# MB9BF32xS register map
File version: 1.0
CPU: 
Registers are 8-bit, read-write, reset 0x0 unless marked. A register's access mark holds for its fields unless they carry their own. Offsets are from the block's base; [hi:lo] are bit positions; {n}, {i} and the like mark numbered series.

## RTC — peripheral RTC
Base 0x4003B000
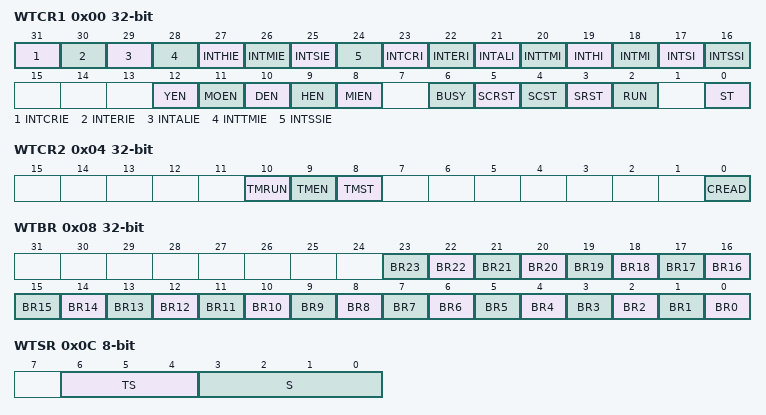
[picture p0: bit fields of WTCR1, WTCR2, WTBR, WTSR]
0x00 WTCR1 32-bit
  [31] INTCRIE, [30] INTERIE, [29] INTALIE, [28] INTTMIE, [27] INTHIE, [26] INTMIE, [25] INTSIE, [24] INTSSIE, [23] INTCRI, [22] INTERI, [21] INTALI, [20] INTTMI, [19] INTHI, [18] INTMI, [17] INTSI, [16] INTSSI, [12] YEN, [11] MOEN, [10] DEN, [9] HEN, [8] MIEN, [6] BUSY ro, [5] SCRST, [4] SCST, [3] SRST, [2] RUN ro, [0] ST
0x04 WTCR2 32-bit
  [10] TMRUN ro, [9] TMEN, [8] TMST, [0] CREAD
0x08 WTBR 32-bit
  [n] BR{n} (n=0..23)
0x0C WTSR
  [6:4] TS, [3:0] S
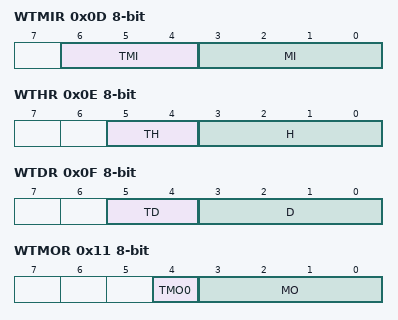
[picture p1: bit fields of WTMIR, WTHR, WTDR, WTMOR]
0x0D WTMIR
  [6:4] TMI, [3:0] MI
0x0E WTHR
  [5:4] TH, [3:0] H
0x0F WTDR
  [5:4] TD, [3:0] D
0x10 WTDW
  [2:0] DW
0x11 WTMOR
  [4] TMO0, [3:0] MO
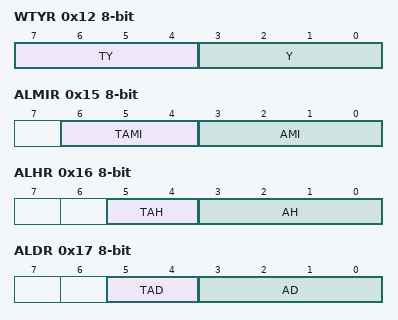
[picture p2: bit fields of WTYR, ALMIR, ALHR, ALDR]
0x12 WTYR
  [7:4] TY, [3:0] Y
0x15 ALMIR
  [6:4] TAMI, [3:0] AMI
0x16 ALHR
  [5:4] TAH, [3:0] AH
0x17 ALDR
  [5:4] TAD, [3:0] AD
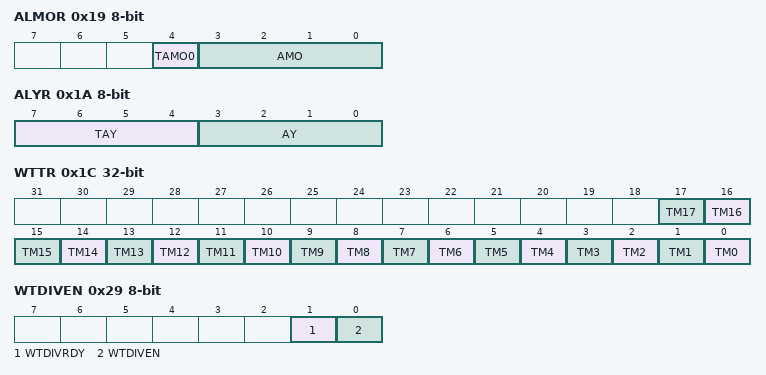
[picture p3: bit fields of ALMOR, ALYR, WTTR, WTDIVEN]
0x19 ALMOR
  [4] TAMO0, [3:0] AMO
0x1A ALYR
  [7:4] TAY, [3:0] AY
0x1C WTTR 32-bit
  [n] TM{n} (n=0..17)
0x20 WTCLKS
  [0] WTCLKS
0x21 WTCLKM ro
  [1:0] WTCLKM
0x24 WTCAL 16-bit
  [9:0] WTCAL
0x26 WTCALEN
  [0] WTCALEN
0x28 WTDIV
  [3:0] WTDIV
0x29 WTDIVEN
  [1] WTDIVRDY ro, [0] WTDIVEN
0x2C WTCALPRD reset 0x13
  [5:0] WTCALPRD
0x30 WTCOSEL
  [0] WTCOSEL

## CRC — peripheral CRC
Base 0x40039000
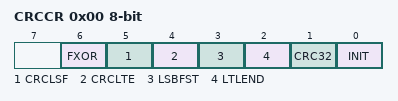
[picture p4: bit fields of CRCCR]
0x00 CRCCR
  [6] FXOR, [5] CRCLSF, [4] CRCLTE, [3] LSBFST, [2] LTLEND, [1] CRC32, [0] INIT
0x04 CRCINIT 32-bit reset 0xFFFFFFFF
  [31:0] D
0x08 CRCIN 32-bit
  [31:0] D
0x0C CRCR 32-bit ro reset 0xFFFFFFFF
  [31:0] D

## EXBUS — peripheral EXBUS
Base 0x4003F000
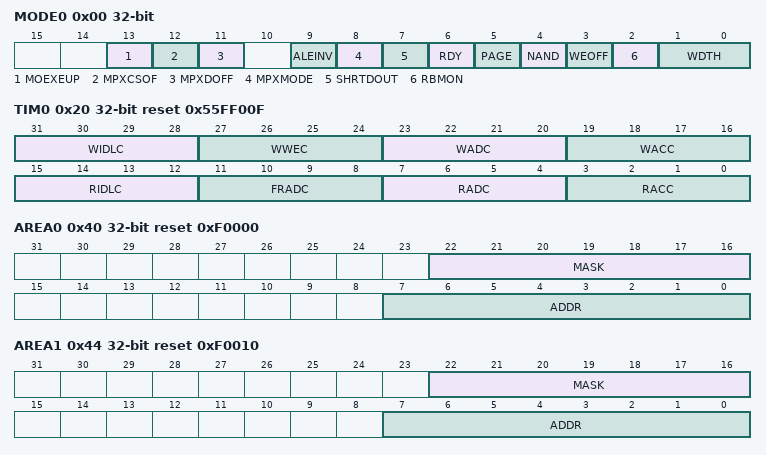
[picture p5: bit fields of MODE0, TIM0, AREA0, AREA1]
0x00 MODE0 32-bit
  [13] MOEXEUP, [12] MPXCSOF, [11] MPXDOFF, [9] ALEINV, [8] MPXMODE, [7] SHRTDOUT, [6] RDY, [5] PAGE, [4] NAND, [3] WEOFF, [2] RBMON, [1:0] WDTH
{0x0+4i} MODE{i} 32-bit reset not defined (i=1..7)
0x20 TIM0 32-bit reset 0x55FF00F
  [31:28] WIDLC, [27:24] WWEC, [23:20] WADC, [19:16] WACC, [15:12] RIDLC, [11:8] FRADC, [7:4] RADC, [3:0] RACC
{0x20+4i} TIM{i} 32-bit reset not defined (i=1..7)
0x40 AREA0 32-bit reset 0xF0000
  [22:16] MASK, [7:0] ADDR
0x44 AREA1 32-bit reset 0xF0010
  [22:16] MASK, [7:0] ADDR
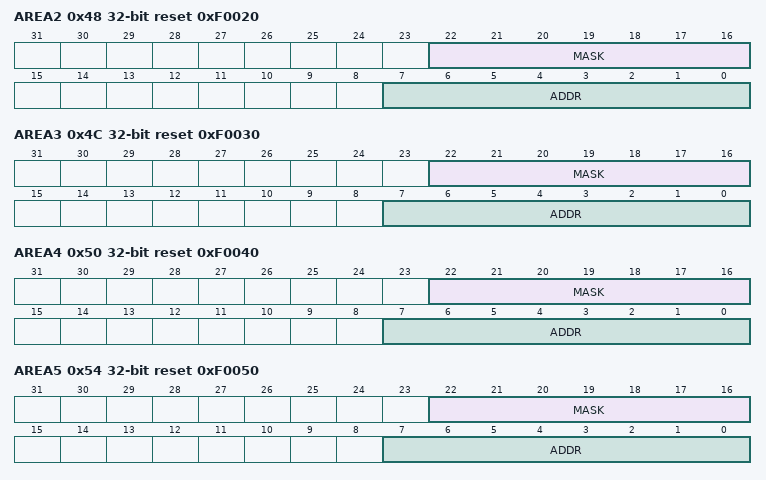
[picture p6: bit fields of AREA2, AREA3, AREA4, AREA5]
0x48 AREA2 32-bit reset 0xF0020
  [22:16] MASK, [7:0] ADDR
0x4C AREA3 32-bit reset 0xF0030
  [22:16] MASK, [7:0] ADDR
0x50 AREA4 32-bit reset 0xF0040
  [22:16] MASK, [7:0] ADDR
0x54 AREA5 32-bit reset 0xF0050
  [22:16] MASK, [7:0] ADDR
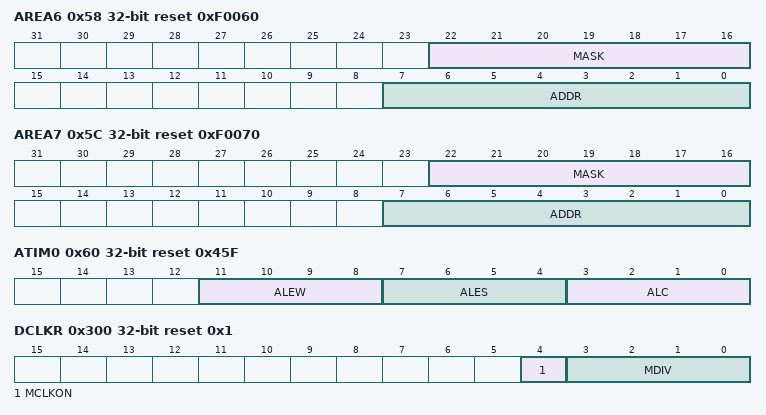
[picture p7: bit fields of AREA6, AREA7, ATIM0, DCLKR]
0x58 AREA6 32-bit reset 0xF0060
  [22:16] MASK, [7:0] ADDR
0x5C AREA7 32-bit reset 0xF0070
  [22:16] MASK, [7:0] ADDR
0x60 ATIM0 32-bit reset 0x45F
  [11:8] ALEW, [7:4] ALES, [3:0] ALC
{0x60+4i} ATIM{i} 32-bit reset not defined (i=1..7)
0x300 DCLKR 32-bit reset 0x1 (reset mask 0xF)
  [4] MCLKON, [3:0] MDIV

## USBCLK — peripheral USBCLK
Base 0x40036000
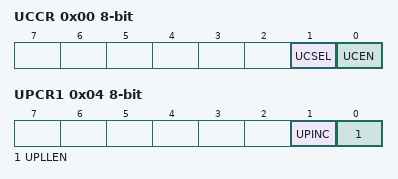
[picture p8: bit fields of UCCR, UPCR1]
0x00 UCCR
  [1] UCSEL, [0] UCEN
0x04 UPCR1
  [1] UPINC, [0] UPLLEN
0x08 UPCR2
  [2:0] UPOWT
0x0C UPCR3
  [4:0] UPLLK
0x10 UPCR4 reset 0x17
  [4:0] UPLLN
0x14 UP_STR ro
  [0] UPRDY
0x18 UPINT_ENR
  [0] UPCSE
0x1C UPINT_CLR wo
  [0] UPCSC
0x20 UPINT_STR ro
  [0] UPCSI
0x24 UPCR5 reset 0x4
  [3:0] UPLLM
0x30 USBEN
  [0] USBEN

## USB0 — peripheral USB0
Base 0x40040000
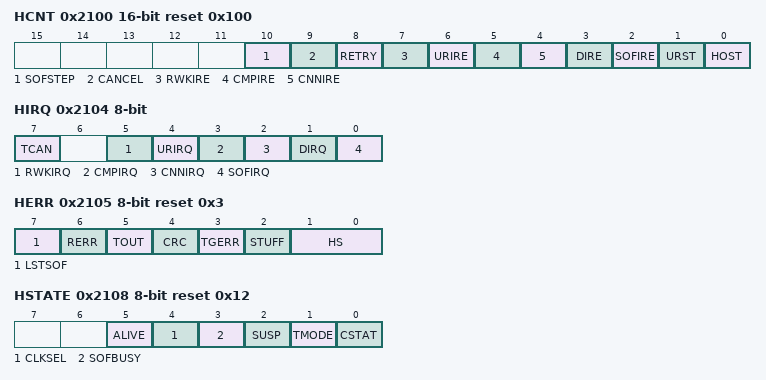
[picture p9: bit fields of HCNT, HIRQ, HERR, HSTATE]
0x2100 HCNT 16-bit reset 0x100
  [10] SOFSTEP, [9] CANCEL, [8] RETRY, [7] RWKIRE, [6] URIRE, [5] CMPIRE, [4] CNNIRE, [3] DIRE, [2] SOFIRE, [1] URST, [0] HOST
0x2104 HIRQ
  [7] TCAN, [5] RWKIRQ, [4] URIRQ, [3] CMPIRQ, [2] CNNIRQ, [1] DIRQ, [0] SOFIRQ
0x2105 HERR reset 0x3
  [7] LSTSOF, [6] RERR, [5] TOUT, [4] CRC, [3] TGERR, [2] STUFF, [1:0] HS
0x2108 HSTATE reset 0x12
  [5] ALIVE, [4] CLKSEL, [3] SOFBUSY, [2] SUSP, [1] TMODE ro, [0] CSTAT ro
0x2109 HFCOMP
  [7:0] FRAMECOMP
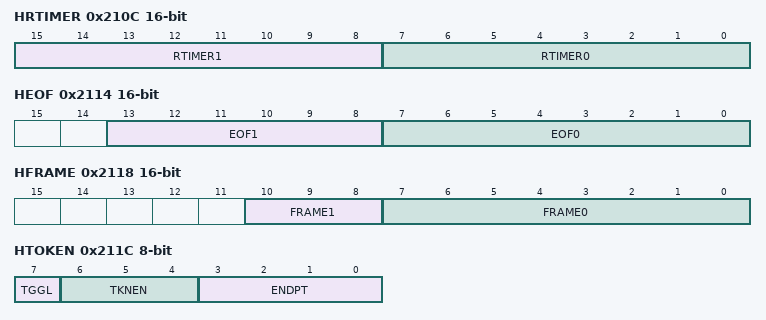
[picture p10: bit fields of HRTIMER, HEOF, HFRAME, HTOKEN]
0x210C HRTIMER 16-bit
  [15:8] RTIMER1, [7:0] RTIMER0
0x2110 HRTIMER2
  [1:0] RTIMER2
0x2111 HADR
  [6:0] ADDRESS
0x2114 HEOF 16-bit
  [13:8] EOF1, [7:0] EOF0
0x2118 HFRAME 16-bit
  [10:8] FRAME1, [7:0] FRAME0
0x211C HTOKEN
  [7] TGGL, [6:4] TKNEN, [3:0] ENDPT
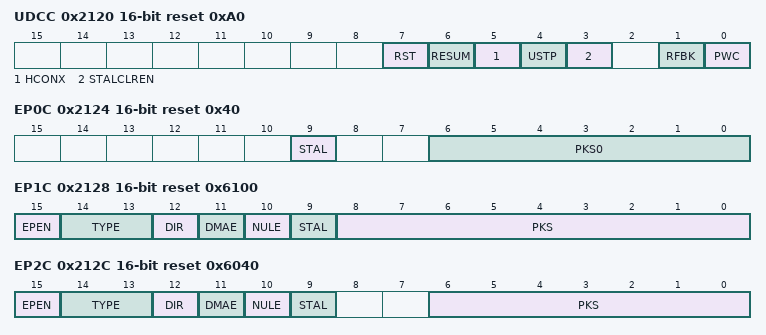
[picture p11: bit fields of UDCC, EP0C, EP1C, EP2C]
0x2120 UDCC 16-bit reset 0xA0
  [7] RST, [6] RESUM, [5] HCONX, [4] USTP, [3] STALCLREN, [1] RFBK, [0] PWC
0x2124 EP0C 16-bit reset 0x40
  [9] STAL, [6:0] PKS0
0x2128 EP1C 16-bit reset 0x6100
  [15] EPEN, [14:13] TYPE, [12] DIR, [11] DMAE, [10] NULE, [9] STAL, [8:0] PKS
0x212C EP2C 16-bit reset 0x6040
  [15] EPEN, [14:13] TYPE, [12] DIR, [11] DMAE, [10] NULE, [9] STAL, [6:0] PKS
{0x2124+4i} EP{i}C 32-bit reset not defined (i=3..5)
0x213C TMSP 16-bit ro
  [10:0] TMSP
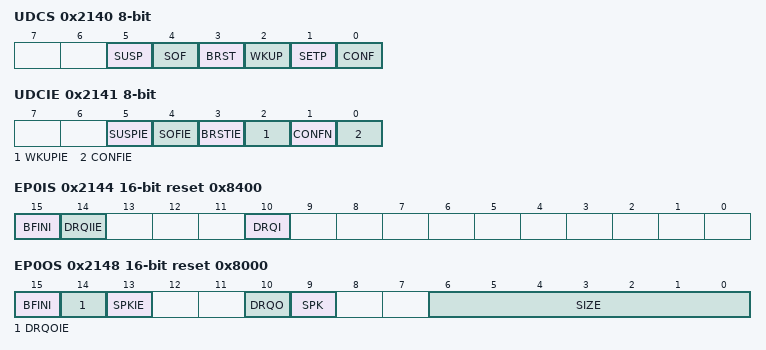
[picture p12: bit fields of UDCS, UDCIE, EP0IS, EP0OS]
0x2140 UDCS
  [5] SUSP, [4] SOF, [3] BRST, [2] WKUP, [1] SETP, [0] CONF
0x2141 UDCIE
  [5] SUSPIE, [4] SOFIE, [3] BRSTIE, [2] WKUPIE, [1] CONFN ro, [0] CONFIE
0x2144 EP0IS 16-bit reset 0x8400
  [15] BFINI, [14] DRQIIE, [10] DRQI
0x2148 EP0OS 16-bit reset 0x8000
  [15] BFINI, [14] DRQOIE, [13] SPKIE, [10] DRQO, [9] SPK, [6:0] SIZE ro
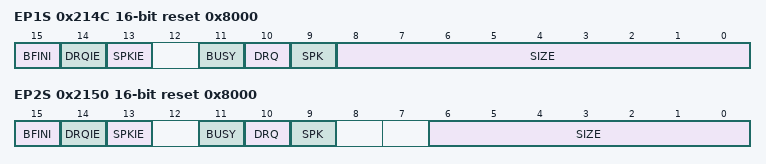
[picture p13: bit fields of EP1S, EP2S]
0x214C EP1S 16-bit reset 0x8000
  [15] BFINI, [14] DRQIE, [13] SPKIE, [11] BUSY ro, [10] DRQ, [9] SPK, [8:0] SIZE ro
0x2150 EP2S 16-bit reset 0x8000
  [15] BFINI, [14] DRQIE, [13] SPKIE, [11] BUSY ro, [10] DRQ, [9] SPK, [6:0] SIZE ro
{0x2148+4i} EP{i}S 32-bit reset not defined (i=3..5)
0x2160 EP0DT 16-bit reset not defined
  [15:0] BFDT
{0x2160+4i} EP{i}DT 32-bit reset not defined (i=1..5)

## DMAC — peripheral DMAC
Base 0x40060000
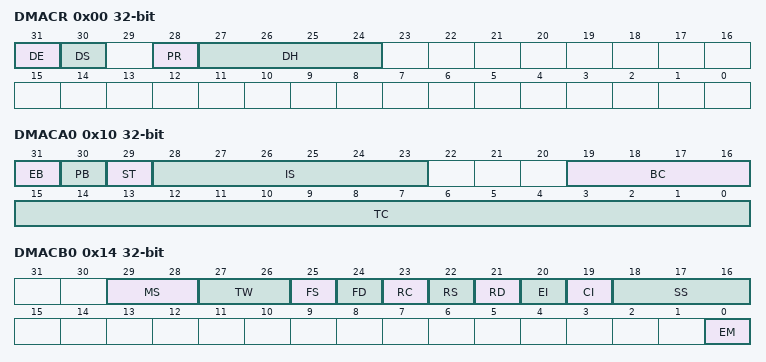
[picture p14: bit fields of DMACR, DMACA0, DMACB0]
0x00 DMACR 32-bit
  [31] DE, [30] DS, [28] PR, [27:24] DH
0x10 DMACA0 32-bit
  [31] EB, [30] PB, [29] ST, [28:23] IS, [19:16] BC, [15:0] TC
0x14 DMACB0 32-bit
  [29:28] MS, [27:26] TW, [25] FS, [24] FD, [23] RC, [22] RS, [21] RD, [20] EI, [19] CI, [18:16] SS, [0] EM
0x18 DMACSA0 32-bit
0x1C DMACDA0 32-bit
{0x10+0x10*i} DMACA{i} 32-bit reset not defined (i=1..7)
{0x14+0x10*i} DMACB{i} 32-bit reset not defined (i=1..7)
{0x18+0x10*i} DMACSA{i} 32-bit reset not defined (i=1..7)
{0x1C+0x10*i} DMACDA{i} 32-bit reset not defined (i=1..7)
